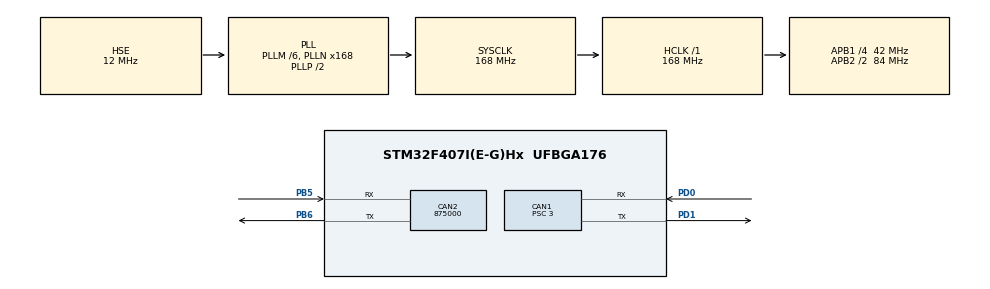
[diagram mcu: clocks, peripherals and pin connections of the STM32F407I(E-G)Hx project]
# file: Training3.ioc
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CAN1.ABOM=ENABLE
CAN1.BS1=CAN_BS1_9TQ
CAN1.BS2=CAN_BS2_4TQ
CAN1.CalculateBaudRate=1000000
CAN1.CalculateTimeBit=1000
CAN1.CalculateTimeQuantum=71.42857142857143
CAN1.NART=ENABLE
CAN1.Prescaler=3
CAN2.BS1=CAN_BS1_1TQ
CAN2.BS2=CAN_BS2_1TQ
CAN2.CalculateBaudRate=875000
CAN2.CalculateTimeBit=1142
CAN2.CalculateTimeQuantum=380.95238095238096
Mcu.Family=STM32F4
Mcu.Name=STM32F407I(E-G)Hx
Mcu.Package=UFBGA176
NVIC.CAN1_RX0_IRQn=true\:5\:0\:true\:false\:true\:true\:true\:true
NVIC.CAN1_TX_IRQn=true\:5\:0\:true\:false\:true\:true\:true\:true
NVIC.PriorityGroup=NVIC_PRIORITYGROUP_4
NVIC.TIM6_DAC_IRQn=true\:6\:0\:true\:false\:true\:true\:true\:true
PB5.Mode=CAN_Activate
PB5.Signal=CAN2_RX
PB6.Mode=CAN_Activate
PB6.Signal=CAN2_TX
PD0.Mode=CAN_Activate
PD0.Signal=CAN1_RX
PD1.Mode=CAN_Activate
PD1.Signal=CAN1_TX
PH0-OSC_IN.Mode=HSE-External-Oscillator
PH0-OSC_IN.Signal=RCC_OSC_IN
PH1-OSC_OUT.Mode=HSE-External-Oscillator
PH1-OSC_OUT.Signal=RCC_OSC_OUT
ProjectManager.HeapSize=0x200
ProjectManager.StackSize=0x400
ProjectManager.TargetToolchain=MDK-ARM V5.32
RCC.48MHZClocksFreq_Value=84000000
RCC.AHBFreq_Value=168000000
RCC.APB1CLKDivider=RCC_HCLK_DIV4
RCC.APB1Freq_Value=42000000
RCC.APB1TimFreq_Value=84000000
RCC.APB2CLKDivider=RCC_HCLK_DIV2
RCC.APB2Freq_Value=84000000
RCC.APB2TimFreq_Value=168000000
RCC.CortexFreq_Value=168000000
RCC.HCLKFreq_Value=168000000
RCC.HSE_VALUE=12000000
RCC.HSI_VALUE=16000000
RCC.LSE_VALUE=32768
RCC.PLLM=6
RCC.PLLN=168
RCC.PLLSourceVirtual=RCC_PLLSOURCE_HSE
RCC.SYSCLKFreq_VALUE=168000000
RCC.SYSCLKSource=RCC_SYSCLKSOURCE_PLLCLK
RCC.VCOOutputFreq_Value=336000000
TIM6.AutoReloadPreload=TIM_AUTORELOAD_PRELOAD_ENABLE
TIM6.Period=999
TIM6.Prescaler=83
VP_TIM6_VS_ClockSourceINT.Mode=Enable_Timer
board=custom

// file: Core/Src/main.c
/* USER CODE BEGIN Header */
/**
  ******************************************************************************
  * @file           : main.c
  * @brief          : Main program body
  ******************************************************************************
  * @attention
  *
  * Copyright (c) 2026 STMicroelectronics.
  * All rights reserved.
  *
  * This software is licensed under terms that can be found in the LICENSE file
  * in the root directory of this software component.
  * If no LICENSE file comes with this software, it is provided AS-IS.
  *
  ******************************************************************************
  */
/* USER CODE END Header */
#include "main.h"
#include "can.h"
#include "tim.h"
#include "gpio.h"

/* USER CODE BEGIN Includes */
#include "can_user.h"
extern void SetMotorCurrent(void);
/* USER CODE END Includes */

void SystemClock_Config(void);

int main(void)
{

  /* MCU Configuration--------------------------------------------------------*/

  /* Reset of all peripherals, Initializes the Flash interface and the Systick. */
  HAL_Init();

  /* Configure the system clock */
  SystemClock_Config();

  /* Initialize all configured peripherals */
  MX_GPIO_Init();
  MX_CAN1_Init();
  MX_CAN2_Init();
  MX_TIM6_Init();
  /* USER CODE BEGIN 2 */
  if (HAL_CAN_ConfigFilter(&hcan1, &can_filter_config) != HAL_OK ||
      HAL_CAN_Start(&hcan1) != HAL_OK ||
      HAL_CAN_ActivateNotification(&hcan1, CAN_IT_RX_FIFO0_MSG_PENDING) != HAL_OK ||
      HAL_TIM_Base_Start_IT(&htim6) != HAL_OK) {
    Error_Handler();
      }
  SetMotorCurrent();
  /* USER CODE END 2 */

  /* Infinite loop */
  while (1)
  {

  }
}

void SystemClock_Config(void)
{
  RCC_OscInitTypeDef RCC_OscInitStruct = {0};
  RCC_ClkInitTypeDef RCC_ClkInitStruct = {0};

  /** Configure the main internal regulator output voltage
  */
  __HAL_RCC_PWR_CLK_ENABLE();
  __HAL_PWR_VOLTAGESCALING_CONFIG(PWR_REGULATOR_VOLTAGE_SCALE1);

  /** Initializes the RCC Oscillators according to the specified parameters
  * in the RCC_OscInitTypeDef structure.
  */
  RCC_OscInitStruct.OscillatorType = RCC_OSCILLATORTYPE_HSE;
  RCC_OscInitStruct.HSEState = RCC_HSE_ON;
  RCC_OscInitStruct.PLL.PLLState = RCC_PLL_ON;
  RCC_OscInitStruct.PLL.PLLSource = RCC_PLLSOURCE_HSE;
  RCC_OscInitStruct.PLL.PLLM = 6;
  RCC_OscInitStruct.PLL.PLLN = 168;
  RCC_OscInitStruct.PLL.PLLP = RCC_PLLP_DIV2;
  RCC_OscInitStruct.PLL.PLLQ = 4;
  if (HAL_RCC_OscConfig(&RCC_OscInitStruct) != HAL_OK)
  {
    Error_Handler();
  }

  /** Initializes the CPU, AHB and APB buses clocks
  */
  RCC_ClkInitStruct.ClockType = RCC_CLOCKTYPE_HCLK|RCC_CLOCKTYPE_SYSCLK
                              |RCC_CLOCKTYPE_PCLK1|RCC_CLOCKTYPE_PCLK2;
  RCC_ClkInitStruct.SYSCLKSource = RCC_SYSCLKSOURCE_PLLCLK;
  RCC_ClkInitStruct.AHBCLKDivider = RCC_SYSCLK_DIV1;
  RCC_ClkInitStruct.APB1CLKDivider = RCC_HCLK_DIV4;
  RCC_ClkInitStruct.APB2CLKDivider = RCC_HCLK_DIV2;

  if (HAL_RCC_ClockConfig(&RCC_ClkInitStruct, FLASH_LATENCY_5) != HAL_OK)
  {
    Error_Handler();
  }
}

void Error_Handler(void)
{
  __disable_irq();
  while (1)
  {
  }
}
